VERSION ""

NS_ :

BS_:

BU_: Charger BMU
VAL_TABLE_ NormalError 1 "Error" 0 "Normal" ;
VAL_TABLE_ ChargeStartStop 1 "ChargeStart" 0 "ChargeStop" ;

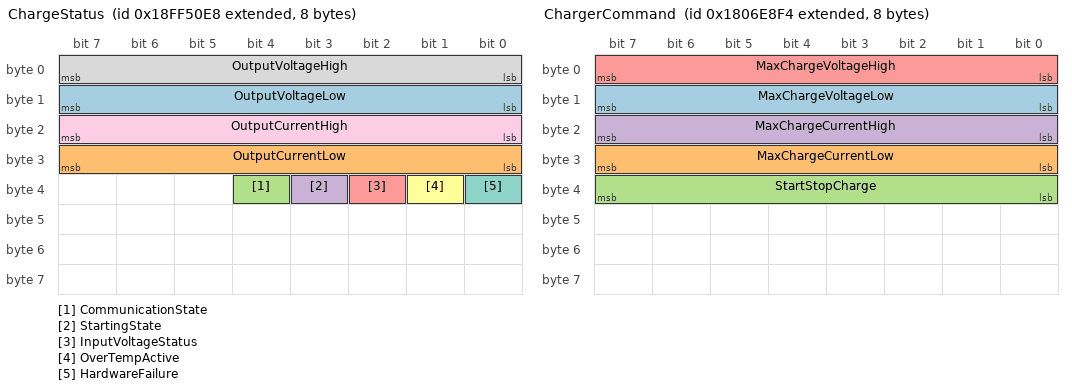
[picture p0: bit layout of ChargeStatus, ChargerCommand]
BO_ 2566869224 ChargeStatus: 8 Charger
 SG_ OutputVoltageLow : 8|8@1+ (1,0) [0|0] "raw"  BMU
 SG_ OutputCurrentLow : 24|8@1+ (1,0) [0|0] "raw"  BMU
 SG_ CommunicationState : 36|1@1+ (1,0) [0|0] ""  BMU
 SG_ StartingState : 35|1@1+ (1,0) [0|0] ""  BMU
 SG_ InputVoltageStatus : 34|1@1+ (1,0) [0|0] ""  BMU
 SG_ OverTempActive : 33|1@1+ (1,0) [0|0] ""  BMU
 SG_ HardwareFailure : 32|1@1+ (1,0) [0|0] ""  BMU
 SG_ OutputVoltageHigh : 0|8@1+ (1,0) [0|0] "raw"  BMU
 SG_ OutputCurrentHigh : 16|8@1+ (1,0) [0|0] "raw"  BMU

BO_ 2550589684 ChargerCommand: 8 BMU
 SG_ MaxChargeVoltageLow : 8|8@1+ (1,0) [0|0] "raw" Vector__XXX
 SG_ MaxChargeCurrentLow : 24|8@1+ (1,0) [0|0] "raw" Vector__XXX
 SG_ StartStopCharge : 32|8@1+ (1,0) [0|0] "" Vector__XXX
 SG_ MaxChargeCurrentHigh : 16|8@1+ (1,0) [0|0] "raw" Vector__XXX
 SG_ MaxChargeVoltageHigh : 0|8@1+ (1,0) [0|0] "raw" Vector__XXX

BA_DEF_ SG_  "SigType" ENUM  "Default","Range","RangeSigned","ASCII","Discrete","Control","ReferencePGN","DTC","StringDelimiter","StringLength","StringLengthControl","MessageCounter","MessageChecksum";
BA_DEF_ SG_  "GenSigEVName" STRING ;
BA_DEF_ SG_  "GenSigILSupport" ENUM  "No","Yes";
BA_DEF_ SG_  "GenSigSendType" ENUM  "Cyclic","OnWrite","OnWriteWithRepetition","OnChange","OnChangeWithRepetition","IfActive","IfActiveWithRepetition","NoSigSendType";
BA_DEF_ BO_  "GenMsgILSupport" ENUM  "No","Yes";
BA_DEF_ BU_  "NmStationAddress" INT 0 255;
BA_DEF_ BO_  "GenMsgSendType" ENUM  "cyclic","NotUsed","IfActive","NotUsed","NotUsed","NotUsed","NotUsed","NotUsed","noMsgSendType";
BA_DEF_ BO_  "GenMsgRequestable" INT 0 1;
BA_DEF_  "DBName" STRING ;
BA_DEF_  "BusType" STRING ;
BA_DEF_  "ProtocolType" STRING ;
BA_DEF_ BO_  "VFrameFormat" ENUM  "StandardCAN","ExtendedCAN","reserved","J1939PG";
BA_DEF_DEF_  "SigType" "Default";
BA_DEF_DEF_  "GenSigEVName" "Env@Nodename_@Signame";
BA_DEF_DEF_  "GenSigILSupport" "Yes";
BA_DEF_DEF_  "GenSigSendType" "NoSigSendType";
BA_DEF_DEF_  "GenMsgILSupport" "Yes";
BA_DEF_DEF_  "NmStationAddress" 254;
BA_DEF_DEF_  "GenMsgSendType" "noMsgSendType";
BA_DEF_DEF_  "GenMsgRequestable" 1;
BA_DEF_DEF_  "DBName" "";
BA_DEF_DEF_  "BusType" "CAN";
BA_DEF_DEF_  "ProtocolType" "J1939";
BA_DEF_DEF_  "VFrameFormat" "J1939PG";
BA_ "DBName" "ChargerMessages";
BA_ "NmStationAddress" BU_ Charger 229;
BA_ "NmStationAddress" BU_ BMU 244;
VAL_ 2566869224 CommunicationState 1 "Error" 0 "Normal" ;
VAL_ 2566869224 StartingState 1 "Error" 0 "Normal" ;
VAL_ 2566869224 InputVoltageStatus 1 "Error" 0 "Normal" ;
VAL_ 2566869224 OverTempActive 1 "Error" 0 "Normal" ;
VAL_ 2566869224 HardwareFailure 1 "Error" 0 "Normal" ;
VAL_ 2550589684 StartStopCharge 1 "ChargeStop" 0 "ChargeStart" ;
